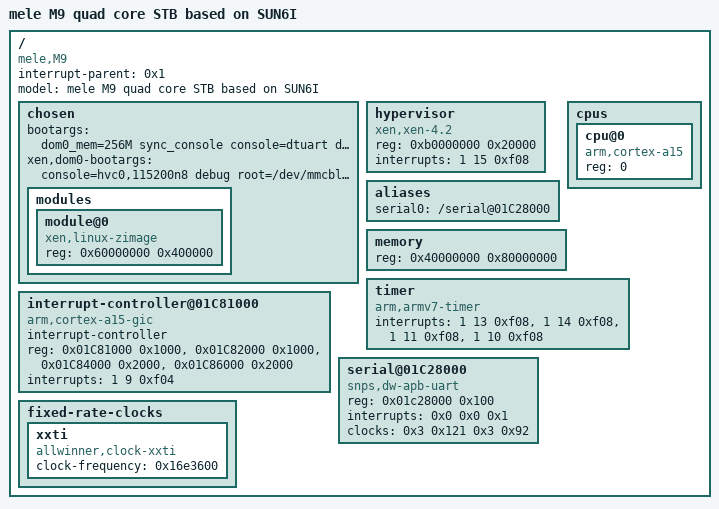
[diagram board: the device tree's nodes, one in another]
/dts-v1/;

/ {
	#address-cells = <0x1>;
	#size-cells = <0x1>;
	compatible = "mele,M9", "allwinner,sun6i";
	interrupt-parent = <0x1>;
	model = "mele M9 quad core STB based on SUN6I";

	chosen {
		bootargs = "dom0_mem=256M sync_console console=dtuart dtuart=serial0";
		xen,dom0-bootargs = "console=hvc0,115200n8 debug root=/dev/mmcblk1p3 ignore_loglevel rw rootwait earlyprintk=xen";
		modules {
			module@0 {
				compatible = "xen,linux-zimage", "xen,multiboot-module";
				reg = <0x60000000 0x400000>;
			};
		};
	};

	hypervisor {
		compatible = "xen,xen-4.2", "xen,xen";
		reg = <0xb0000000 0x20000>;
		interrupts = <1 15 0xf08>;
	};

	aliases {
		serial0 = "/serial@01C28000";
	};

	cpus {
		#address-cells = <1>;
		#size-cells = <0>;

		cpu@0 {
			device_type = "cpu";
			compatible = "arm,cortex-a15";
			reg = <0>;
		};
	};

	memory {
		device_type = "memory";
		reg = <0x40000000 0x80000000>;
	};

	timer {
                compatible = "arm,armv7-timer";
                interrupts = <1 13 0xf08>,
                             <1 14 0xf08>,
                             <1 11 0xf08>,
                             <1 10 0xf08>;
        };

	interrupt-controller@01C81000 {
		compatible = "arm,cortex-a15-gic", "arm,cortex-a9-gic";
		#interrupt-cells = <0x3>;
		interrupt-controller;
		linux,phandle = <0x1>;
		phandle = <0x1>;
/*
		#address-cells = <0>;
*/
		reg = <0x01C81000 0x1000>,
			<0x01C82000 0x1000>,
			<0x01C84000 0x2000>,
			<0x01C86000 0x2000>;
		interrupts = <1 9 0xf04>;
	};

	serial@01C28000 {
		compatible = "snps,dw-apb-uart";
		reg = <0x01c28000 0x100>;
		interrupts = <0x0 0x0 0x1>;
		clocks = <0x3 0x121 0x3 0x92>;
		clock-names = "uart", "clk_uart_baud0";
	};

	fixed-rate-clocks {

		xxti {
			compatible = "allwinner,clock-xxti";
			clock-frequency = <0x16e3600>;
		};
	};
};
